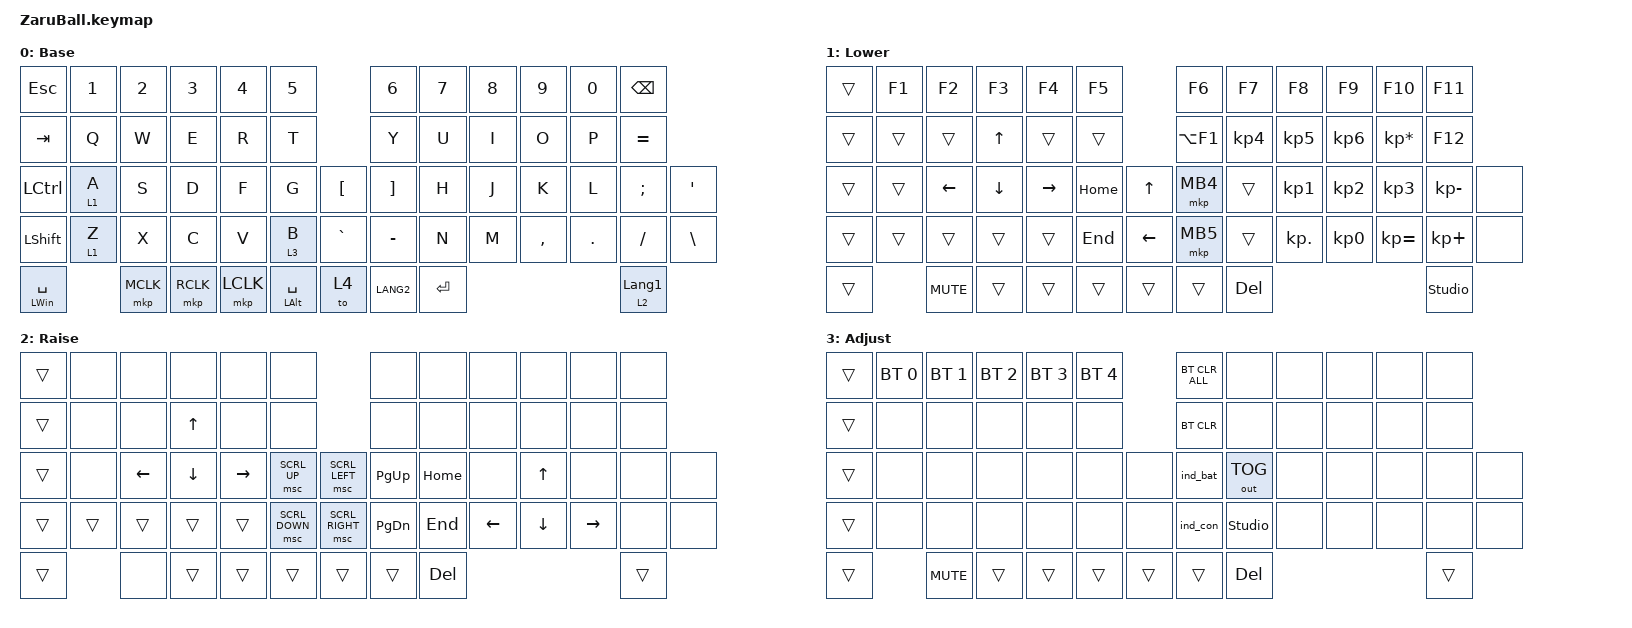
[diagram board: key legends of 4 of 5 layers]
//#include <dt-bindings/zmk/mouse.h>

#include <behaviors/rgbled_widget.dtsi>
#include <behaviors.dtsi>
#include <dt-bindings/zmk/bt.h>
#include <dt-bindings/zmk/keys.h>
#include <dt-bindings/zmk/outputs.h>
#include <dt-bindings/zmk/pointing.h>

#define BASE 0
#define LOWER 1
#define RAISE 2
#define ADJUST 3
#define MOUSE 4
#define SCROLL 1

// スクロール量の設定

#define ZMK_POINTING_DEFAULT_SCRL_VAL 100

/ {
    conditional_layers { compatible = "zmk,conditional-layers"; };
};

/ {
    behaviors {
        // スクロール用のbehaviorの設定

        scroll_up_down: behavior_sensor_rotate_mouse_wheel_up_down {
            compatible = "zmk,behavior-sensor-rotate";
            #sensor-binding-cells = <0>;
            bindings = <&msc SCRL_UP>, <&msc SCRL_DOWN>;

            tap-ms = <20>; // スクロールのタップ時間
        };

        td0: tap_dance_0 {
            compatible = "zmk,behavior-tap-dance";
            #binding-cells = <0>;
            tapping-term-ms = <200>;
            bindings = <&mt LEFT_SHIFT LANG2>, <&mo RAISE>, <&mo MOUSE>;
        };

        td1: tap_dance_1 {
            compatible = "zmk,behavior-tap-dance";
            #binding-cells = <0>;
            tapping-term-ms = <200>;
            bindings = <&mt RCTL LANG1>, <&mo RAISE>, <&mo 5>;
        };
    };
};

&sl { release-after-ms = <250>; }; // time needed for double click (for mkp_exit_AML)
/ {
    macros {
        // When in AML, move to default layer when key (except mouse button) pressed

        to_layer_0: to_layer_0 {
            compatible = "zmk,behavior-macro-one-param";
            #binding-cells = <1>;
            bindings = <&to BASE &macro_param_1to1 &kp MACRO_PLACEHOLDER>;
            label = "TO_layer_0";
        };

        // When LCLK pressed, exit AML (after 250ms cause by sticky layer)

        mkp_exit_AML: mkp_exit_AML {
            compatible = "zmk,behavior-macro-one-param";
            #binding-cells = <1>;
            bindings =
                <&macro_press>,
                <&macro_param_1to1 &mkp MACRO_PLACEHOLDER>,
                <&macro_pause_for_release>,
                <&macro_release>,
                <&macro_param_1to1 &mkp MACRO_PLACEHOLDER>,
                <&macro_tap>,
                <&sl MOUSE>;

            label = "MKP_EXIT_AML";
        };

        // Support swapping into Scroll layer when AML is activated

        to_scroll_layer: to_scroll_layer {
            compatible = "zmk,behavior-macro";
            #binding-cells = <0>;
            bindings =
                <&to SCROLL>,
                <&macro_press>,
                <&mo SCROLL>,
                <&macro_pause_for_release>,
                <&macro_release>,
                <&mo SCROLL>;
        };
    };
};

/ {
    keymap {
        compatible = "zmk,keymap";

        base_layer {
            display-name = "Base";
            sensor-bindings = <&inc_dec_kp C_VOLUME_UP C_VOLUME_DOWN>;
            bindings = <
&kp ESC             &kp N1   &kp N2     &kp N3     &kp N4     &kp N5                         &kp NUMBER_6  &kp N7     &kp N8  &kp N9     &kp N0   &kp BACKSPACE
&kp TAB             &kp Q    &kp W      &kp E      &kp R      &kp T                          &kp Y         &kp U      &kp I   &kp O      &kp P    &kp EQUAL
&kp LCTRL           &lt 1 A  &kp S      &kp D      &kp F      &kp G               &kp LBKT   &kp RBKT      &kp H      &kp J   &kp K      &kp L    &kp SEMI          &kp SQT
&kp LEFT_SHIFT      &lt 1 Z  &kp X      &kp C      &kp V      &lt 3 B             &kp GRAVE  &kp MINUS     &kp N      &kp M   &kp COMMA  &kp DOT  &kp FSLH          &kp BACKSLASH
&mt LEFT_WIN SPACE           &mkp MCLK  &mkp RCLK  &mkp LCLK  &mt LEFT_ALT SPACE  &to 4      &kp LANG2     &kp ENTER                              &lt 2 LANGUAGE_1
            >;
        };

        function_layer {
            display-name = "Lower";
            sensor-bindings = <&inc_dec_kp C_VOLUME_UP C_VOLUME_DOWN>;
            bindings = <
&trans  &kp F1  &kp F2          &kp F3          &kp F4           &kp F5                  &kp F6      &kp F7     &kp F8      &kp F9     &kp F10          &kp F11
&trans  &trans  &trans          &kp UP_ARROW    &trans           &trans                  &kp LA(F1)  &kp KP_N4  &kp KP_N5   &kp KP_N6  &kp KP_MULTIPLY  &kp F12
&trans  &trans  &kp LEFT_ARROW  &kp DOWN_ARROW  &kp RIGHT_ARROW  &kp HOME  &kp UP_ARROW  &mkp MB4    &trans     &kp KP_N1   &kp KP_N2  &kp KP_N3        &kp KP_MINUS    &none
&trans  &trans  &trans          &trans          &trans           &kp END   &kp LEFT      &mkp MB5    &trans     &kp KP_DOT  &kp KP_N0  &kp KP_EQUAL     &kp KP_PLUS     &none
&trans          &kp K_MUTE      &trans          &trans           &trans    &trans        &trans      &kp DEL                                            &studio_unlock
            >;
        };

        raise_layer {
            display-name = "Raise";
            sensor-bindings = <&inc_dec_kp K_SCROLL_UP K_SCROLL_DOWN>;
            bindings = <
&trans  &none   &none           &none           &none            &none                            &none      &none     &none     &none     &none      &none
&trans  &none   &none           &kp UP_ARROW    &none            &none                            &none      &none     &none     &none     &none      &none
&trans  &none   &kp LEFT_ARROW  &kp DOWN_ARROW  &kp RIGHT_ARROW  &msc SCRL_UP    &msc SCRL_LEFT   &kp PG_UP  &kp HOME  &none     &kp UP    &none      &none   &none
&trans  &trans  &trans          &trans          &trans           &msc SCRL_DOWN  &msc SCRL_RIGHT  &kp PG_DN  &kp END   &kp LEFT  &kp DOWN  &kp RIGHT  &none   &none
&trans          &none           &trans          &trans           &trans          &trans           &trans     &kp DEL                                  &trans
            >;
        };

        adjust_layer {
            display-name = "Adjust";
            sensor-bindings = <&inc_dec_kp C_VOL_UP C_VOL_DN>;
            bindings = <
&trans  &bt BT_SEL 0  &bt BT_SEL 1  &bt BT_SEL 2  &bt BT_SEL 3  &bt BT_SEL 4          &bt BT_CLR_ALL  &none           &none  &none  &none  &none
&trans  &none         &none         &none         &none         &none                 &bt BT_CLR      &none           &none  &none  &none  &none
&trans  &none         &none         &none         &none         &none         &none   &ind_bat        &out OUT_TOG    &none  &none  &none  &none   &none
&trans  &none         &none         &none         &none         &none         &none   &ind_con        &studio_unlock  &none  &none  &none  &none   &none
&trans                &kp C_MUTE    &trans        &trans        &trans        &trans  &trans          &kp DEL                              &trans
            >;
        };

        mouse_layer {
            display-name = "Mouse";
            sensor-bindings = <&scroll_up_down>;
            bindings = <
&to_layer_0 ESC             &to_layer_0 N1  &to_layer_0 N2  &to_layer_0 N3  &to_layer_0 N4      &to_layer_0 N5                     &to_layer_0 N6   &to_layer_0 N7  &to_layer_0 N8  &to_layer_0 N9  &to_layer_0 N0      &to_layer_0 MINUS
&to_layer_0 TAB             &to_layer_0 Q   &to_layer_0 W   &to_layer_0 E   &to_layer_0 R       &to_layer_0 T                      &kp LG(W)        &to_layer_0 U   &to_layer_0 I   &to_layer_0 O   &to_layer_0 P       &to_layer_0 EQUAL
&to_layer_0 CAPS            &to_layer_0 A   &mkp RCLK       &mkp MCLK       &mkp_exit_AML LCLK  &msc SCRL_UP    &msc SCRL_LEFT     &msc SCRL_LEFT   &msc SCRL_UP    &mkp MB1        &mkp MB2        &mkp MB3            &to_layer_0 SINGLE_QUOTE  &to_layer_0 SEMICOLON
&to_layer_0 LSHIFT          &to_layer_0 Z   &to_layer_0 X   &mkp MB4        &mkp MB5            &msc SCRL_DOWN  &msc SCRL_RIGHT    &msc SCRL_RIGHT  &msc SCRL_DOWN  &mkp MB4        &mkp MB5        &to_layer_0 PERIOD  &to_layer_0 SLASH         &mt
&to_scroll_layer BACKSLASH                  &trans          &trans          &trans              &trans          &to_layer_0 SPACE  &trans           &trans                                                              &trans
            >;
        };

        // Extra layer can be added in ZMK STUDIO

        extra1 { status = "reserved"; };

        extra2 { status = "reserved"; };
    };
};
